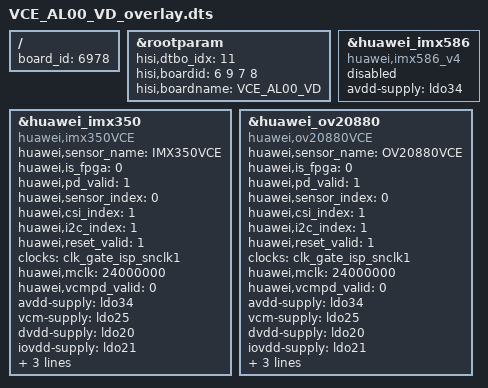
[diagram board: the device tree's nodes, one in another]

/**
 * Copyright (C) 2014 Hisilicon Ltd.
 *
 *  This program is free software; you can redistribute it and/or modify
 *  it under the terms of the GNU General Public License version 2 as
 *  publishhed by the Free Software Foundation.
 */

/dts-v1/;
/plugin/;
/include/ "VCE_AL00_VC_overlay.dtsi"

/ {
	board_id = <6978>;
};
&rootparam {
        hisi,dtbo_idx = <11>;
    hisi,boardid = <6 9 7 8>;
    hisi,boardname = "VCE_AL00_VD";
};

&huawei_imx586 {
	compatible = "huawei,imx586_v4";
	avdd-supply = <&ldo34>;
	status = "disable";
};

&huawei_imx350 {
	compatible = "huawei,imx350VCE";
	huawei,sensor_name = "IMX350VCE";
	huawei,is_fpga = <0>;
	huawei,pd_valid = <1>;
	huawei,sensor_index = <0>;
	huawei,csi_index = <1>;
	huawei,i2c_index = <1>;
	huawei,reset_valid = <1>;
	clock-names = "clk_isp_snclk1";
	clocks = <&clk_gate_isp_snclk1>;
	huawei,mclk = <24000000>;
	huawei,vcmpd_valid = <0>;
	avdd-supply = <&ldo34>;
	vcm-supply = <&ldo25>;
	dvdd-supply = <&ldo20>;
	iovdd-supply = <&ldo21>;
	huawei,ldo-names = "avdd", "vcm", "dvdd", "iovdd";
	gpios = <&gpio1 5 0>;
	huawei,gpio-ctrl-types = "reset";
	status = "ok";
};

&huawei_ov20880 {
	compatible = "huawei,ov20880VCE";
	huawei,sensor_name = "OV20880VCE";
	huawei,is_fpga = <0>;
	huawei,pd_valid = <1>;
	huawei,sensor_index = <0>;
	huawei,csi_index = <1>;
	huawei,i2c_index = <1>;
	huawei,reset_valid = <1>;
	clock-names = "clk_isp_snclk1";
	clocks = <&clk_gate_isp_snclk1>;
	huawei,mclk = <24000000>;
	huawei,vcmpd_valid = <0>;
	avdd-supply = <&ldo34>;
	vcm-supply = <&ldo25>;
	dvdd-supply = <&ldo20>;
	iovdd-supply = <&ldo21>;
	huawei,ldo-names = "avdd", "vcm", "dvdd", "iovdd";
	gpios = <&gpio1 5 0>;
	huawei,gpio-ctrl-types = "reset";
	status = "ok";
};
